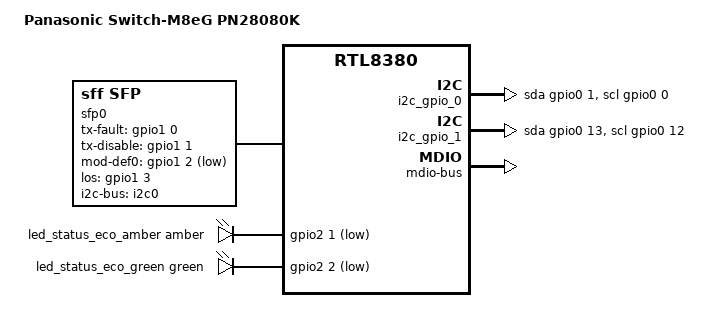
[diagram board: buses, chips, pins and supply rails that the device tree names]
// SPDX-License-Identifier: GPL-2.0-or-later OR MIT

#include "rtl838x.dtsi"
#include "rtl83xx_panasonic_mxxeg-pn28xx0k.dtsi"

#include <dt-bindings/interrupt-controller/irq.h>

/ {
	compatible = "panasonic,m8eg-pn28080k", "realtek,rtl8380-soc";
	model = "Panasonic Switch-M8eG PN28080K";

	aliases {
		led-boot = &led_status_eco_green;
		led-failsafe = &led_status_eco_amber;
		led-running = &led_status_eco_green;
		led-upgrade = &led_status_eco_green;
	};

	sfp0: sfp-p9 {
		compatible = "sff,sfp";
		i2c-bus = <&i2c0>;
		tx-fault-gpio = <&gpio1 0 GPIO_ACTIVE_HIGH>;
		tx-disable-gpio = <&gpio1 1 GPIO_ACTIVE_HIGH>;
		mod-def0-gpio = <&gpio1 2 GPIO_ACTIVE_LOW>;
		los-gpio = <&gpio1 3 GPIO_ACTIVE_HIGH>;
	};
};

&leds {
	led_status_eco_amber: led-5 {
		gpios = <&gpio2 1 GPIO_ACTIVE_LOW>;
		color = <LED_COLOR_ID_AMBER>;
		function = LED_FUNCTION_STATUS;
		function-enumerator = <1>;
	};

	led_status_eco_green: led-6 {
		gpios = <&gpio2 2 GPIO_ACTIVE_LOW>;
		color = <LED_COLOR_ID_GREEN>;
		function = LED_FUNCTION_STATUS;
		function-enumerator = <2>;
	};
};

&i2c_gpio_0 {
	scl-gpios = <&gpio0 0 (GPIO_ACTIVE_HIGH | GPIO_OPEN_DRAIN)>;
	sda-gpios = <&gpio0 1 (GPIO_ACTIVE_HIGH | GPIO_OPEN_DRAIN)>;
};

&i2c_gpio_1 {
	scl-gpios = <&gpio0 12 (GPIO_ACTIVE_HIGH | GPIO_OPEN_DRAIN)>;
	sda-gpios = <&gpio0 13 (GPIO_ACTIVE_HIGH | GPIO_OPEN_DRAIN)>;
};

&gpio1 {
	interrupt-controller;
	#interrupt-cells = <2>;
	interrupt-parent = <&gpio0>;
	interrupts = <2 IRQ_TYPE_EDGE_FALLING>;
};

&gpio2 {
	interrupt-controller;
	#interrupt-cells = <2>;
	interrupt-parent = <&gpio0>;
	interrupts = <2 IRQ_TYPE_EDGE_FALLING>;
};

&i2c_switch {
	i2c0: i2c@0 {
		#address-cells = <1>;
		#size-cells = <0>;
		reg = <0>;
	};
};

&ethernet0 {
	mdio-bus {
		compatible = "realtek,rtl838x-mdio";
		regmap = <&ethernet0>;
		#address-cells = <1>;
		#size-cells = <0>;

		INTERNAL_PHY(8)
		INTERNAL_PHY(9)
		INTERNAL_PHY(10)
		INTERNAL_PHY(11)
		INTERNAL_PHY(12)
		INTERNAL_PHY(13)
		INTERNAL_PHY(14)
		INTERNAL_PHY(15)

		INTERNAL_PHY(24)
	};
};

&switch0 {
	ports {
		#address-cells = <1>;
		#size-cells = <0>;

		SWITCH_PORT(8, 1, internal)
		SWITCH_PORT(9, 2, internal)
		SWITCH_PORT(10, 3, internal)
		SWITCH_PORT(11, 4, internal)
		SWITCH_PORT(12, 5, internal)
		SWITCH_PORT(13, 6, internal)
		SWITCH_PORT(14, 7, internal)
		SWITCH_PORT(15, 8, internal)

		port@24 {
			reg = <24>;
			label = "lan9";
			phy-mode = "1000base-x";
			phy-handle = <&phy24>;
			managed = "in-band-status";
			sfp = <&sfp0>;
		};

		port@28 {
			ethernet = <&ethernet0>;
			reg = <28>;
			phy-mode = "internal";

			fixed-link {
				speed = <1000>;
				full-duplex;
			};
		};
	};
};
